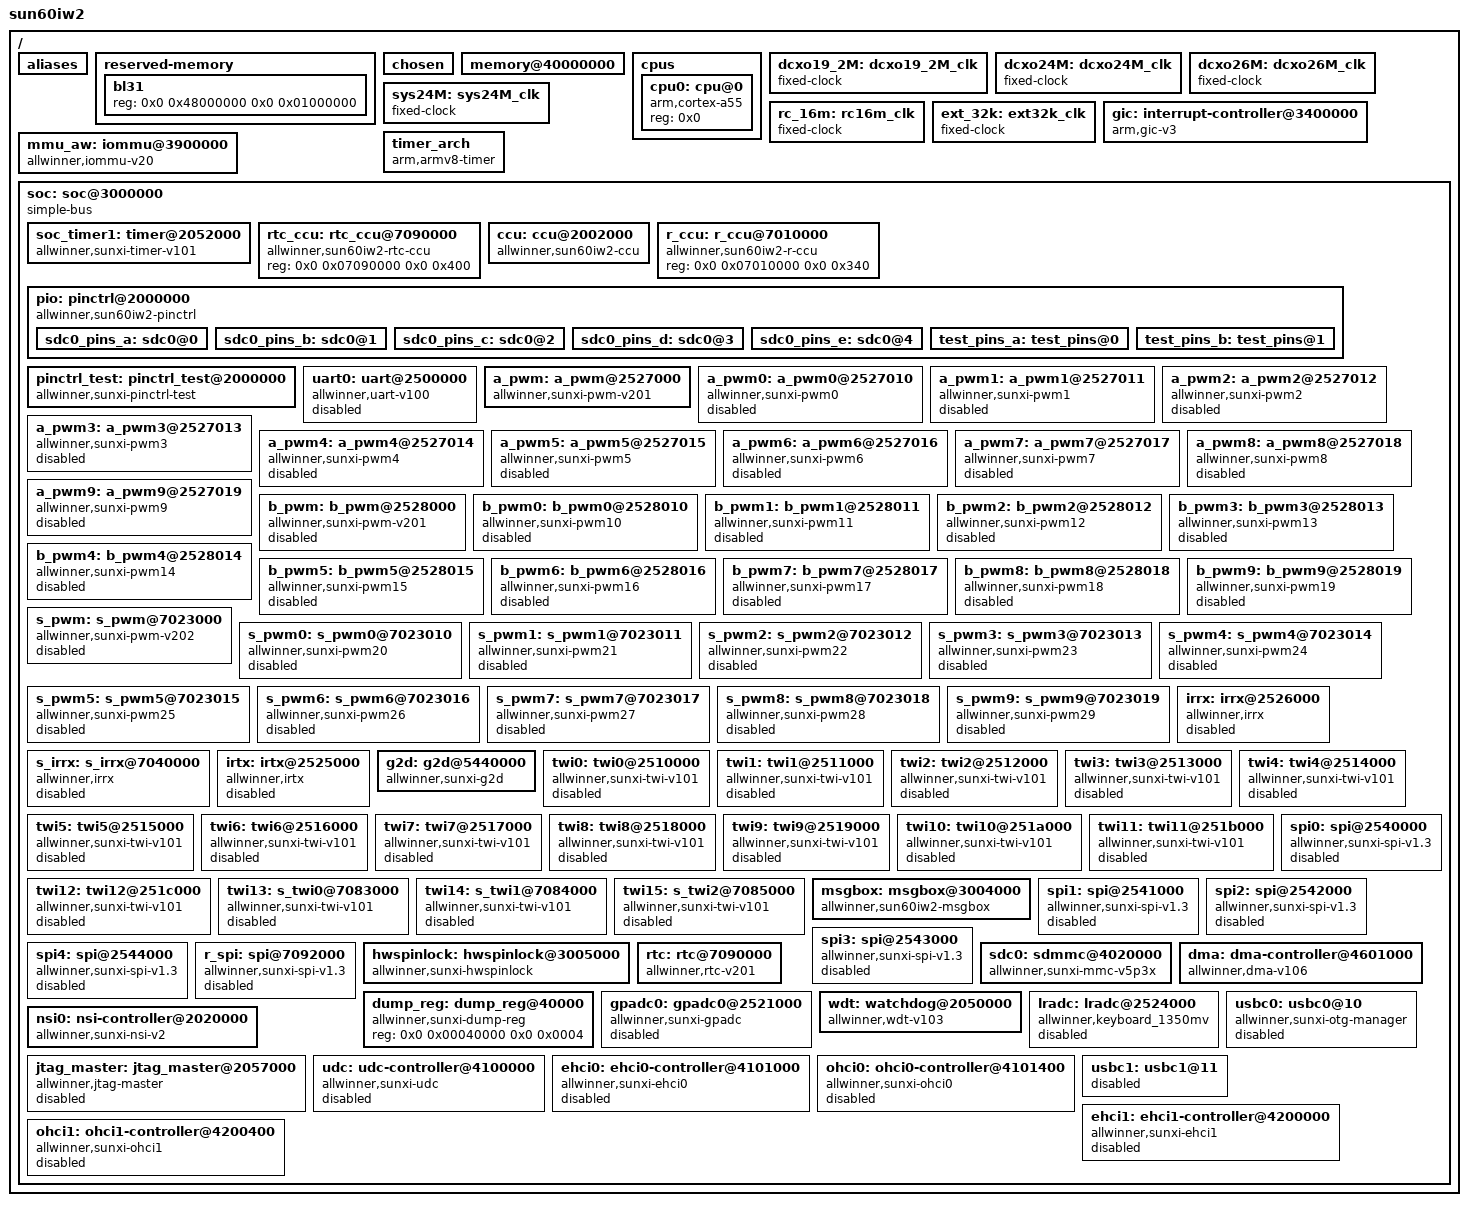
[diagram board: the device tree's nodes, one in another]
// SPDX-License-Identifier: (GPL-2.0+ or MIT)
#include <dt-bindings/clock/sun60iw2-ccu.h>
#include <dt-bindings/clock/sun60iw2-rtc.h>
#include <dt-bindings/clock/sun60iw2-r-ccu.h>
#include <dt-bindings/gpio/gpio.h>
#include <dt-bindings/gpio/sun4i-gpio.h>
#include <dt-bindings/interrupt-controller/arm-gic.h>
#include <dt-bindings/reset/sun60iw2-ccu.h>
#include <dt-bindings/reset/sun60iw2-r-ccu.h>
#include <dt-bindings/power/a523-power.h>
#include <dt-bindings/phy/phy.h>
#include <dt-bindings/thermal/thermal.h>
#include <dt-bindings/spi/sunxi-spi.h>

/ {
	model = "sun60iw2";
	interrupt-parent = <&gic>;
	#address-cells = <2>;
	#size-cells = <2>;

	aliases {
		serial0 = &uart0;
		ir0 = &irrx;
		ir1 = &s_irrx;
		ir2 = &irtx;
		twi0 = &twi0;
		twi1 = &twi1;
		twi2 = &twi2;
		twi3 = &twi3;
		twi4 = &twi4;
		twi5 = &twi5;
		twi6 = &twi6;
		twi7 = &twi7;
		twi8 = &twi8;
		twi9 = &twi9;
		twi10 = &twi10;
		twi11 = &twi11;
		twi12 = &twi12;
		twi13 = &twi13;
		twi14 = &twi14;
		twi15 = &twi15;
		spi0 = &spi0;
		spi1 = &spi1;
		spi2 = &spi2;
		spi3 = &spi3;
		spi4 = &spi4;
		spi5 = &r_spi;
	};

	reserved-memory {
		#address-cells = <2>;
		#size-cells = <2>;
		ranges;

		bl31 {
			reg = <0x0 0x48000000 0x0 0x01000000>;
		};
	};

	chosen {
		bootargs = "earlyprintk=sunxi-uart,0x2500000 loglevel=8 initcall_debug=0 console=ttyS0 init=/init";
		linux,initrd-start = <0x0 0x0>;
		linux,initrd-end = <0x0 0x0>;
	};

	/* avoid panic when memory-node err(from uboot) */
	memory@40000000 {
		device_type = "memory";
		reg = <0x00000000 0x40000000 0x00000000 0x20000000>;
	};

	cpus {
		#address-cells = <1>;
		#size-cells = <0>;

		cpu0: cpu@0 {
			device_type = "cpu";
			compatible = "arm,cortex-a55";
			reg = <0x0>;
		};
	};

	dcxo19_2M: dcxo19_2M_clk {
		#clock-cells = <0>;
		compatible = "fixed-clock";
		clock-frequency = <19200000>;
		clock-output-names = "dcxo19_2M";
	};

	dcxo24M: dcxo24M_clk {
		#clock-cells = <0>;
		compatible = "fixed-clock";
		clock-frequency = <24000000>;
		clock-output-names = "dcxo24M";
	};

	dcxo26M: dcxo26M_clk {
		#clock-cells = <0>;
		compatible = "fixed-clock";
		clock-frequency = <26000000>;
		clock-output-names = "dcxo26M";
	};

	sys24M: sys24M_clk {
		#clock-cells = <0>;
		compatible = "fixed-clock";
		clock-frequency = <24000000>;
		clock-output-names = "sys24M";
	};

	rc_16m: rc16m_clk {
		#clock-cells = <0>;
		compatible = "fixed-clock";
		clock-frequency = <16000000>;
		clock-accuracy = <300000000>;
		clock-output-names = "rc-16m";
	};

	ext_32k: ext32k_clk {
		#clock-cells = <0>;
		compatible = "fixed-clock";
		clock-frequency = <32768>;
		clock-output-names = "ext-32k";
	};

	gic: interrupt-controller@3400000 {
		compatible = "arm,gic-v3";
		#interrupt-cells = <3>;
		#address-cells = <0>;
		interrupt-controller;
		reg = <0x0 0x03400000 0 0x10000>, /* GIC Dist */
		      <0x0 0x03460000 0 0xFF004>; /* GIC Re */
		interrupt-parent = <&gic>;
	};

	timer_arch {
		compatible = "arm,armv8-timer";
		interrupts = <GIC_PPI 13 (GIC_CPU_MASK_SIMPLE(4) | IRQ_TYPE_LEVEL_LOW)>,
			   <GIC_PPI 14 (GIC_CPU_MASK_SIMPLE(4) | IRQ_TYPE_LEVEL_LOW)>,
			   <GIC_PPI 11 (GIC_CPU_MASK_SIMPLE(4) | IRQ_TYPE_LEVEL_LOW)>,
			   <GIC_PPI 10 (GIC_CPU_MASK_SIMPLE(4) | IRQ_TYPE_LEVEL_LOW)>;
		clock-frequency = <24000000>;
		interrupt-parent = <&gic>;
		arm,no-tick-in-suspend;
	};

	mmu_aw: iommu@3900000 {
		compatible = "allwinner,iommu-v20";
		reg = <0x0 0x03900000 0x0 0x20000>;
		interrupts = <GIC_SPI 170 IRQ_TYPE_LEVEL_HIGH>,
		      <GIC_SPI 171 IRQ_TYPE_LEVEL_HIGH>;
		interrupt-names = "iommu-irq1","iommu-irq2";
		clocks = <&ccu CLK_IOMMU0_SYS_HCLK>,
		      <&ccu CLK_IOMMU0_SYS_PCLK>,
		      <&ccu CLK_IOMMU0_SYS_MCLK>,
		      <&ccu CLK_IOMMU1_SYS_HCLK>,
		      <&ccu CLK_IOMMU1_SYS_PCLK>,
		      <&ccu CLK_IOMMU1_SYS_MCLK>
		;
		clock-names = "iommu0-sys-hclk",
		      "iommu0-sys-pclk",
		      "iommu0-sys-mclk",
		      "iommu1-sys-hclk",
		      "iommu1-sys-pclk",
		      "iommu1-sys-mclk"
		;
		/* clock-frequency = <24000000>; */
		#iommu-cells = <2>;
		version=<0x16>;
	tlb_prefetch = <0x3007f>;
	tlb_invalid_mode = <0x1>;
	ptw_invalid_mode = <0x1>;
	masters = "USB", "CSI", "ISP", "VE_ENC", "VE_DEC0",
			"VE_DEC1", "DE0","DI","G2D","EINK", "DEBUG_MODE";
			valid_masters=<10>;
	};

	soc: soc@3000000 {
		compatible = "simple-bus";
		#address-cells = <2>;
		#size-cells = <2>;
		ranges;

		soc_timer1: timer@2052000 {
			compatible = "allwinner,sunxi-timer-v101";
			device_type = "soc_timer";
			reg = <0x0 0x02052000 0x0 0x400>;
			interrupt-parent = <&gic>;
			interrupts = <GIC_SPI 99 IRQ_TYPE_LEVEL_HIGH>;
			clocks = <&rtc_ccu CLK_OSC32K>;
		};

		rtc_ccu: rtc_ccu@7090000 {
			compatible = "allwinner,sun60iw2-rtc-ccu";
			reg = <0x0 0x07090000 0x0 0x400>;
			#clock-cells = <1>;
			#reset-cells = <1>;
		};

		ccu: ccu@2002000 {
			compatible = "allwinner,sun60iw2-ccu";
			reg = <0x0 0x02002000 0x0 0x2000>;
			clocks = <&dcxo24M>, <&rtc_ccu CLK_OSC32K>, <&rc_16m>;
			clock-names = "hosc", "losc", "iosc";
			#clock-cells = <1>;
			#reset-cells = <1>;
		};

		r_ccu: r_ccu@7010000 {
			compatible = "allwinner,sun60iw2-r-ccu";
			reg = <0x0 0x07010000 0x0 0x340>;
			#clock-cells = <1>;
			#reset-cells = <1>;
		};

		pio: pinctrl@2000000 {
			//#address-cells = <1>;
			//#size-cells = <0>;
			compatible = "allwinner,sun60iw2-pinctrl";
			reg = <0x0 0x02000000 0x0 0x800>;
			interrupts = <GIC_SPI 69 IRQ_TYPE_LEVEL_HIGH>,
				     <GIC_SPI 71 IRQ_TYPE_LEVEL_HIGH>,
				     <GIC_SPI 73 IRQ_TYPE_LEVEL_HIGH>,
				     <GIC_SPI 75 IRQ_TYPE_LEVEL_HIGH>,
				     <GIC_SPI 77 IRQ_TYPE_LEVEL_HIGH>,
				     <GIC_SPI 79 IRQ_TYPE_LEVEL_HIGH>,
				     <GIC_SPI 81 IRQ_TYPE_LEVEL_HIGH>;
			clocks = <&ccu CLK_APB1>, <&dcxo24M>, <&rtc_ccu CLK_OSC32K>;
			clock-names = "apb", "hosc", "losc";
			gpio-controller;
			#gpio-cells = <3>;
			interrupt-controller;
			#interrupt-cells = <3>;

			sdc0_pins_a: sdc0@0 {
				pins = "PF0", "PF1", "PF2",
						"PF3", "PF4", "PF5";
				function = "sd0";
				drive-strength = <40>;
				bias-pull-up;
				power-source = <3300>;
			};

			sdc0_pins_b: sdc0@1 {
				pins = "PF0", "PF1", "PF2",
						"PF3", "PF4", "PF5";
				function = "sd0";
				drive-strength = <40>;
				bias-pull-up;
				power-source = <1800>;
			};

			sdc0_pins_c: sdc0@2 {
				pins = "PF0", "PF1", "PF2",
						"PF3", "PF4", "PF5";
				function = "gpio_in";
			};

			/* TODO: add jtag pin */
			sdc0_pins_d: sdc0@3 {
				pins = "PF2", "PF4";
				function = "uart0";
				drive-strength = <10>;
				bias-pull-up;
			};

			sdc0_pins_e: sdc0@4 {
				pins = "PF0", "PF1", "PF3",
						"PF5";
				function = "jtag";
				drive-strength = <10>;
				bias-pull-up;
			};
			test_pins_a: test_pins@0 {
				pins = "PB0", "PB1";
				function = "test";
				drive-strength = <10>;
				bias-pull-up;
			};

			test_pins_b: test_pins@1 {
				pins = "PB0", "PB1";
				function = "gpio_in";
			};
		};

		pinctrl_test: pinctrl_test@2000000 {
		      reg = <0x0 0x0 0x0 0x0>;
		      compatible = "allwinner,sunxi-pinctrl-test";
		      device_type = "pinctrl-test";
		      pinctrl-0 = <&test_pins_a>;
		      pinctrl-1 = <&test_pins_b>;
		      pinctrl-names = "default", "sleep";
		      test-gpios = <&pio PB 4 GPIO_ACTIVE_LOW>;
		      suspend-gpios = <&pio PC 5 GPIO_ACTIVE_LOW>;
		      wakeup-source;
		      interrupt-parent = <&pio>;
		      interrupts = <PB 6 IRQ_TYPE_LEVEL_HIGH>;
		};
		uart0: uart@2500000 {
			compatible = "allwinner,uart-v100";
			reg = <0x0 0x02500000 0x0 0x400>;
			interrupts = <GIC_SPI 2 IRQ_TYPE_LEVEL_HIGH>;
			clocks = <&ccu CLK_UART0>;
			resets = <&ccu RST_BUS_UART0>;
			uart0_port = <0>;
			uart0_type = <2>;
			status = "disabled";
		};

		a_pwm: a_pwm@2527000 {
			#pwm-cells = <0x3>;
			compatible = "allwinner,sunxi-pwm-v201";
			reg = <0x0 0x02527000 0x0 0x400>;
			clocks = <&ccu CLK_PWM0>;
			interrupts = <GIC_SPI 35 IRQ_TYPE_LEVEL_HIGH>;
			resets = <&ccu RST_BUS_PWM0>;
			pwm-number = <10>;
			pwm-base = <0x0>;
			sunxi-pwms = <&a_pwm0>, <&a_pwm1>, <&a_pwm2>, <&a_pwm3>, <&a_pwm4>,
			<&a_pwm5>, <&a_pwm6>, <&a_pwm7>, <&a_pwm8>, <&a_pwm9>;
			status = "okay";
		};

		a_pwm0: a_pwm0@2527010 {
			compatible = "allwinner,sunxi-pwm0";
			pinctrl-names = "active", "sleep";
			reg = <0x0 0x02527010 0x0 0x4>;
			reg_base = <0x02527000>;
			status = "disabled";
		};

		a_pwm1: a_pwm1@2527011 {
			compatible = "allwinner,sunxi-pwm1";
			pinctrl-names = "active", "sleep";
			reg = <0x0 0x02527011 0x0 0x4>;
			reg_base = <0x02527000>;
			status = "disabled";
		};

		a_pwm2: a_pwm2@2527012 {
			compatible = "allwinner,sunxi-pwm2";
			pinctrl-names = "active", "sleep";
			reg = <0x0 0x02527012 0x0 0x4>;
			reg_base = <0x02527000>;
			status = "disabled";
		};

		a_pwm3: a_pwm3@2527013 {
			compatible = "allwinner,sunxi-pwm3";
			pinctrl-names = "active", "sleep";
			reg = <0x0 0x02527013 0x0 0x4>;
			reg_base = <0x02527000>;
			status = "disabled";
		};

		a_pwm4: a_pwm4@2527014 {
			compatible = "allwinner,sunxi-pwm4";
			pinctrl-names = "active", "sleep";
			reg = <0x0 0x02527014 0x0 0x4>;
			reg_base = <0x02527000>;
			status = "disabled";
		};

		a_pwm5: a_pwm5@2527015 {
			compatible = "allwinner,sunxi-pwm5";
			pinctrl-names = "active", "sleep";
			reg = <0x0 0x02527015 0x0 0x4>;
			reg_base = <0x02527000>;
			status = "disabled";
		};

		a_pwm6: a_pwm6@2527016 {
			compatible = "allwinner,sunxi-pwm6";
			pinctrl-names = "active", "sleep";
			reg = <0x0 0x02527016 0x0 0x4>;
			reg_base = <0x02527000>;
			status = "disabled";
		};

		a_pwm7: a_pwm7@2527017 {
			compatible = "allwinner,sunxi-pwm7";
			pinctrl-names = "active", "sleep";
			reg = <0x0 0x02527017 0x0 0x4>;
			reg_base = <0x02527000>;
			status = "disabled";
		};

		a_pwm8: a_pwm8@2527018 {
			compatible = "allwinner,sunxi-pwm8";
			pinctrl-names = "active", "sleep";
			reg = <0x0 0x02527018 0x0 0x4>;
			reg_base = <0x02527000>;
			status = "disabled";
		};

		a_pwm9: a_pwm9@2527019 {
			compatible = "allwinner,sunxi-pwm9";
			pinctrl-names = "active", "sleep";
			reg = <0x0 0x02527019 0x0 0x4>;
			reg_base = <0x02527000>;
			status = "disabled";
		};

		b_pwm: b_pwm@2528000 {
			#pwm-cells = <0x3>;
			compatible = "allwinner,sunxi-pwm-v201";
			reg = <0x0 0x02528000 0x0 0x400>;
			clocks = <&ccu CLK_PWM1>;
			interrupts = <GIC_SPI 36 IRQ_TYPE_LEVEL_HIGH>;
			resets = <&ccu RST_BUS_PWM1>;
			pwm-number = <10>;
			pwm-base = <0xa>;
			sunxi-pwms = <&b_pwm0>, <&b_pwm1>, <&b_pwm2>, <&b_pwm3>,
			<&b_pwm4>, <&b_pwm5>, <&b_pwm6>, <&b_pwm7>, <&b_pwm8>, <&b_pwm9>;
			status = "disabled";
		};

		b_pwm0: b_pwm0@2528010 {
			compatible = "allwinner,sunxi-pwm10";
			pinctrl-names = "active", "sleep";
			reg = <0x0 0x02528010 0x0 0x4>;
			reg_base = <0x02528000>;
			status = "disabled";
		};

		b_pwm1: b_pwm1@2528011 {
			compatible = "allwinner,sunxi-pwm11";
			pinctrl-names = "active", "sleep";
			reg = <0x0 0x02528011 0x0 0x4>;
			reg_base = <0x02528000>;
			status = "disabled";
		};

		b_pwm2: b_pwm2@2528012 {
			compatible = "allwinner,sunxi-pwm12";
			pinctrl-names = "active", "sleep";
			reg = <0x0 0x02528012 0x0 0x4>;
			reg_base = <0x02528000>;
			status = "disabled";
		};

		b_pwm3: b_pwm3@2528013 {
			compatible = "allwinner,sunxi-pwm13";
			pinctrl-names = "active", "sleep";
			reg = <0x0 0x02528013 0x0 0x4>;
			reg_base = <0x02528000>;
			status = "disabled";
		};

		b_pwm4: b_pwm4@2528014 {
			compatible = "allwinner,sunxi-pwm14";
			pinctrl-names = "active", "sleep";
			reg = <0x0 0x02528014 0x0 0x4>;
			reg_base = <0x02528000>;
			status = "disabled";
		};

		b_pwm5: b_pwm5@2528015 {
			compatible = "allwinner,sunxi-pwm15";
			pinctrl-names = "active", "sleep";
			reg = <0x0 0x02528015 0x0 0x4>;
			reg_base = <0x02528000>;
			status = "disabled";
		};

		b_pwm6: b_pwm6@2528016 {
			compatible = "allwinner,sunxi-pwm16";
			pinctrl-names = "active", "sleep";
			reg = <0x0 0x02528016 0x0 0x4>;
			reg_base = <0x02528000>;
			status = "disabled";
		};

		b_pwm7: b_pwm7@2528017 {
			compatible = "allwinner,sunxi-pwm17";
			pinctrl-names = "active", "sleep";
			reg = <0x0 0x02528017 0x0 0x4>;
			reg_base = <0x02528000>;
			status = "disabled";
		};

		b_pwm8: b_pwm8@2528018 {
			compatible = "allwinner,sunxi-pwm18";
			pinctrl-names = "active", "sleep";
			reg = <0x0 0x02528018 0x0 0x4>;
			reg_base = <0x02528000>;
			status = "disabled";
		};

		b_pwm9: b_pwm9@2528019 {
			compatible = "allwinner,sunxi-pwm19";
			pinctrl-names = "active", "sleep";
			reg = <0x0 0x02528019 0x0 0x4>;
			reg_base = <0x02528000>;
			status = "disabled";
		};

		s_pwm: s_pwm@7023000 {
			#pwm-cells = <0x3>;
			compatible = "allwinner,sunxi-pwm-v202";
			reg = <0x0 0x07023000 0x0 0x400>;
			clocks = <&r_ccu CLK_R_PWM>,<&r_ccu CLK_R_BUS_PWM>;
			interrupts = <GIC_SPI 207 IRQ_TYPE_LEVEL_HIGH>;
			clock-names = "clk_pwm","clk_bus_pwm";
			resets = <&r_ccu RST_BUS_R_PWM>;
			pwm-number = <10>;
			pwm-base = <0x14>;
			sunxi-pwms = <&s_pwm0>, <&s_pwm1>, <&s_pwm2>, <&s_pwm3>,
			<&s_pwm4>, <&s_pwm5>, <&s_pwm6>, <&s_pwm7>, <&s_pwm8>, <&s_pwm9>;
			status = "disabled";
		};

		s_pwm0: s_pwm0@7023010 {
			compatible = "allwinner,sunxi-pwm20";
			pinctrl-names = "active", "sleep";
			reg = <0x0 0x07023010 0x0 0x4>;
			reg_base = <0x07023000>;
			status = "disabled";
		};

		s_pwm1: s_pwm1@7023011 {
			compatible = "allwinner,sunxi-pwm21";
			pinctrl-names = "active", "sleep";
			reg = <0x0 0x07023011 0x0 0x4>;
			reg_base = <0x07023000>;
			status = "disabled";
		};

		s_pwm2: s_pwm2@7023012 {
			compatible = "allwinner,sunxi-pwm22";
			pinctrl-names = "active", "sleep";
			reg = <0x0 0x07023012 0x0 0x4>;
			reg_base = <0x07023000>;
			status = "disabled";
		};

		s_pwm3: s_pwm3@7023013 {
			compatible = "allwinner,sunxi-pwm23";
			pinctrl-names = "active", "sleep";
			reg = <0x0 0x07023013 0x0 0x4>;
			reg_base = <0x07023000>;
			status = "disabled";
		};

		s_pwm4: s_pwm4@7023014 {
			compatible = "allwinner,sunxi-pwm24";
			pinctrl-names = "active", "sleep";
			reg = <0x0 0x07023014 0x0 0x4>;
			reg_base = <0x07023000>;
			status = "disabled";
		};

		s_pwm5: s_pwm5@7023015 {
			compatible = "allwinner,sunxi-pwm25";
			pinctrl-names = "active", "sleep";
			reg = <0x0 0x07023015 0x0 0x4>;
			reg_base = <0x07023000>;
			status = "disabled";
		};

		s_pwm6: s_pwm6@7023016 {
			compatible = "allwinner,sunxi-pwm26";
			pinctrl-names = "active", "sleep";
			reg = <0x0 0x07023016 0x0 0x4>;
			reg_base = <0x07023000>;
			status = "disabled";
		};

		s_pwm7: s_pwm7@7023017 {
			compatible = "allwinner,sunxi-pwm27";
			pinctrl-names = "active", "sleep";
			reg = <0x0 0x07023017 0x0 0x4>;
			reg_base = <0x07023000>;
			status = "disabled";
		};

		s_pwm8: s_pwm8@7023018 {
			compatible = "allwinner,sunxi-pwm28";
			pinctrl-names = "active", "sleep";
			reg = <0x0 0x07023018 0x0 0x4>;
			reg_base = <0x07023000>;
			status = "disabled";
		};

		s_pwm9: s_pwm9@7023019 {
			compatible = "allwinner,sunxi-pwm29";
			pinctrl-names = "active", "sleep";
			reg = <0x0 0x07023019 0x0 0x4>;
			reg_base = <0x07023000>;
			status = "disabled";
		};

		irrx: irrx@2526000 {
			compatible = "allwinner,irrx";
			reg = <0x0 0x02526000 0x0 0x400>;
			interrupts = <GIC_SPI 32 IRQ_TYPE_LEVEL_HIGH>;
			clocks = <&ccu CLK_BUS_IRRX>, <&dcxo24M>, <&ccu CLK_IRRX>;
			clock-names = "bus", "pclk", "mclk";
			resets = <&ccu RST_BUS_IRRX>;
			status = "disabled";
		};

		s_irrx: s_irrx@7040000 {
			compatible = "allwinner,irrx";
			reg = <0x0 0x07040000 0x0 0x400>;
			interrupts = <GIC_SPI 206 IRQ_TYPE_LEVEL_HIGH>;
			clocks = <&r_ccu CLK_R_BUS_IRRX>, <&dcxo24M>, <&r_ccu CLK_R_IRRX>;
			clock-names = "bus", "pclk", "mclk";
			resets = <&r_ccu RST_BUS_R_IRRX>;
			status = "disabled";
		};

		irtx: irtx@2525000 {
			compatible = "allwinner,irtx";
			reg = <0x0 0x02525000 0x0 0x400>;
			interrupts = <GIC_SPI 31 IRQ_TYPE_LEVEL_HIGH>;
			clocks = <&ccu CLK_BUS_IRTX>, <&dcxo24M>, <&ccu CLK_IRTX>;
			clock-names = "bus", "pclk", "mclk";
			resets = <&ccu RST_BUS_IRTX>;
			status = "disabled";
		};

		g2d: g2d@5440000 {
			compatible = "allwinner,sunxi-g2d";
			reg = <0x0 0x05440000 0x0 0x30000>;
			interrupts = <GIC_SPI 51 IRQ_TYPE_LEVEL_HIGH>;
			clocks = <&ccu CLK_BUS_G2D>, <&ccu CLK_G2D>;
			clock-names = "bus", "g2d";
			resets = <&ccu RST_BUS_G2D>;
			iommus = <&mmu_aw 10 1>;
			assigned-clocks = <&ccu CLK_G2D>;
			assigned-clock-rates = <300000000>;
		};

		twi0: twi0@2510000 {
			#address-cells = <1>;
			#size-cells = <0>;
			compatible = "allwinner,sunxi-twi-v101";
			device_type = "twi0";
			reg = <0x0 0x02510000 0x0 0x400>;
			interrupts = <GIC_SPI 11 IRQ_TYPE_LEVEL_HIGH>;
			clocks = <&ccu CLK_TWI0>;
			clock-names = "bus";
			resets = <&ccu RST_BUS_TWI0>;
			dmas = <&dma 37>, <&dma 37>;
			dma-names = "tx", "rx";
			status = "disabled";
		};

		twi1: twi1@2511000 {
			#address-cells = <1>;
			#size-cells = <0>;
			compatible = "allwinner,sunxi-twi-v101";
			device_type = "twi1";
			reg = <0x0 0x02511000 0x0 0x400>;
			interrupts = <GIC_SPI 12 IRQ_TYPE_LEVEL_HIGH>;
			clocks = <&ccu CLK_TWI1>;
			clock-names = "bus";
			resets = <&ccu RST_BUS_TWI1>;
			dmas = <&dma 38>, <&dma 38>;
			dma-names = "tx", "rx";
			status = "disabled";
		};

		twi2: twi2@2512000 {
			#address-cells = <1>;
			#size-cells = <0>;
			compatible = "allwinner,sunxi-twi-v101";
			device_type = "twi2";
			reg = <0x0 0x02512000 0x0 0x400>;
			interrupts = <GIC_SPI 13 IRQ_TYPE_LEVEL_HIGH>;
			clocks = <&ccu CLK_TWI2>;
			clock-names = "bus";
			resets = <&ccu RST_BUS_TWI2>;
			dmas = <&dma 39>, <&dma 39>;
			dma-names = "tx", "rx";
			status = "disabled";
		};

		twi3: twi3@2513000 {
			#address-cells = <1>;
			#size-cells = <0>;
			compatible = "allwinner,sunxi-twi-v101";
			device_type = "twi3";
			reg = <0x0 0x02513000 0x0 0x400>;
			interrupts = <GIC_SPI 14 IRQ_TYPE_LEVEL_HIGH>;
			clocks = <&ccu CLK_TWI3>;
			clock-names = "bus";
			resets = <&ccu RST_BUS_TWI3>;
			dmas = <&dma 40>, <&dma 40>;
			dma-names = "tx", "rx";
			status = "disabled";
		};

		twi4: twi4@2514000 {
			#address-cells = <1>;
			#size-cells = <0>;
			compatible = "allwinner,sunxi-twi-v101";
			device_type = "twi4";
			reg = <0x0 0x02514000 0x0 0x400>;
			interrupts = <GIC_SPI 15 IRQ_TYPE_LEVEL_HIGH>;
			clocks = <&ccu CLK_TWI4>;
			clock-names = "bus";
			resets = <&ccu RST_BUS_TWI4>;
			dmas = <&dma 41>, <&dma 41>;
			dma-names = "tx", "rx";
			status = "disabled";
		};

		twi5: twi5@2515000 {
			#address-cells = <1>;
			#size-cells = <0>;
			compatible = "allwinner,sunxi-twi-v101";
			device_type = "twi5";
			reg = <0x0 0x02515000 0x0 0x400>;
			interrupts = <GIC_SPI 16 IRQ_TYPE_LEVEL_HIGH>;
			clocks = <&ccu CLK_TWI5>;
			clock-names = "bus";
			resets = <&ccu RST_BUS_TWI5>;
			dmas = <&dma 42>, <&dma 42>;
			dma-names = "tx", "rx";
			status = "disabled";
		};

		twi6: twi6@2516000 {
			#address-cells = <1>;
			#size-cells = <0>;
			compatible = "allwinner,sunxi-twi-v101";
			device_type = "twi6";
			reg = <0x0 0x02516000 0x0 0x400>;
			interrupts = <GIC_SPI 17 IRQ_TYPE_LEVEL_HIGH>;
			clocks = <&ccu CLK_TWI6>;
			clock-names = "bus";
			resets = <&ccu RST_BUS_TWI6>;
			dmas = <&dma 43>, <&dma 43>;
			dma-names = "tx", "rx";
			status = "disabled";
		};

		twi7: twi7@2517000 {
			#address-cells = <1>;
			#size-cells = <0>;
			compatible = "allwinner,sunxi-twi-v101";
			device_type = "twi7";
			reg = <0x0 0x02517000 0x0 0x400>;
			interrupts = <GIC_SPI 18 IRQ_TYPE_LEVEL_HIGH>;
			clocks = <&ccu CLK_TWI7>;
			clock-names = "bus";
			resets = <&ccu RST_BUS_TWI7>;
			dmas = <&dma 44>, <&dma 44>;
			dma-names = "tx", "rx";
			status = "disabled";
		};

		twi8: twi8@2518000 {
			#address-cells = <1>;
			#size-cells = <0>;
			compatible = "allwinner,sunxi-twi-v101";
			device_type = "twi8";
			reg = <0x0 0x02518000 0x0 0x400>;
			interrupts = <GIC_SPI 19 IRQ_TYPE_LEVEL_HIGH>;
			clocks = <&ccu CLK_TWI8>;
			clock-names = "bus";
			resets = <&ccu RST_BUS_TWI8>;
			dmas = <&dma 45>, <&dma 45>;
			dma-names = "tx", "rx";
			status = "disabled";
		};

		twi9: twi9@2519000 {
			#address-cells = <1>;
			#size-cells = <0>;
			compatible = "allwinner,sunxi-twi-v101";
			device_type = "twi9";
			reg = <0x0 0x02519000 0x0 0x400>;
			interrupts = <GIC_SPI 20 IRQ_TYPE_LEVEL_HIGH>;
			clocks = <&ccu CLK_TWI9>;
			clock-names = "bus";
			resets = <&ccu RST_BUS_TWI9>;
			dmas = <&dma 58>, <&dma 58>;
			dma-names = "tx", "rx";
			status = "disabled";
		};

		twi10: twi10@251a000 {
			#address-cells = <1>;
			#size-cells = <0>;
			compatible = "allwinner,sunxi-twi-v101";
			device_type = "twi10";
			reg = <0x0 0x0251a000 0x0 0x400>;
			interrupts = <GIC_SPI 21 IRQ_TYPE_LEVEL_HIGH>;
			clocks = <&ccu CLK_TWI10>;
			clock-names = "bus";
			resets = <&ccu RST_BUS_TWI10>;
			dmas = <&dma 59>, <&dma 59>;
			dma-names = "tx", "rx";
			status = "disabled";
		};

		twi11: twi11@251b000 {
			#address-cells = <1>;
			#size-cells = <0>;
			compatible = "allwinner,sunxi-twi-v101";
			device_type = "twi11";
			reg = <0x0 0x0251b000 0x0 0x400>;
			interrupts = <GIC_SPI 22 IRQ_TYPE_LEVEL_HIGH>;
			clocks = <&ccu CLK_TWI11>;
			clock-names = "bus";
			resets = <&ccu RST_BUS_TWI11>;
			dmas = <&dma 60>, <&dma 60>;
			dma-names = "tx", "rx";
			status = "disabled";
		};

		twi12: twi12@251c000 {
			#address-cells = <1>;
			#size-cells = <0>;
			compatible = "allwinner,sunxi-twi-v101";
			device_type = "twi12";
			reg = <0x0 0x0251c000 0x0 0x400>;
			interrupts = <GIC_SPI 23 IRQ_TYPE_LEVEL_HIGH>;
			clocks = <&ccu CLK_TWI12>;
			clock-names = "bus";
			resets = <&ccu RST_BUS_TWI12>;
			dmas = <&dma 61>, <&dma 61>;
			dma-names = "tx", "rx";
			status = "disabled";
		};

		twi13: s_twi0@7083000 {
			#address-cells = <1>;
			#size-cells = <0>;
			compatible = "allwinner,sunxi-twi-v101";
			device_type = "twi13";
			reg = <0x0 0x07083000 0x0 0x400>;
			interrupts = <GIC_SPI 203 IRQ_TYPE_LEVEL_HIGH>;
			clocks = <&r_ccu CLK_R_TWI0>;
			clock-names = "bus";
			resets = <&r_ccu RST_BUS_R_TWI0>;
			dmas = <&dma 47>, <&dma 47>;
			dma-names = "tx", "rx";
			status = "disabled";
		};

		twi14: s_twi1@7084000 {
			#address-cells = <1>;
			#size-cells = <0>;
			compatible = "allwinner,sunxi-twi-v101";
			device_type = "twi14";
			reg = <0x0 0x07084000 0x0 0x400>;
			interrupts = <GIC_SPI 204 IRQ_TYPE_LEVEL_HIGH>;
			clocks = <&r_ccu CLK_R_TWI1>;
			clock-names = "bus";
			resets = <&r_ccu RST_BUS_R_TWI1>;
			dmas = <&dma 48>, <&dma 48>;
			dma-names = "tx", "rx";
			status = "disabled";
		};

		twi15: s_twi2@7085000 {
			#address-cells = <1>;
			#size-cells = <0>;
			compatible = "allwinner,sunxi-twi-v101";
			device_type = "twi15";
			reg = <0x0 0x07085000 0x0 0x400>;
			interrupts = <GIC_SPI 205 IRQ_TYPE_LEVEL_HIGH>;
			clocks = <&r_ccu CLK_R_TWI>;
			clock-names = "bus";
			resets = <&r_ccu RST_BUS_R_TWI>;
			dmas = <&dma 49>, <&dma 49>;
			dma-names = "tx", "rx";
			status = "disabled";
		};

		/*
		 * channel0~3  : arm -> cpus
		 */
		msgbox: msgbox@3004000 {
			compatible = "allwinner,sun60iw2-msgbox";
			#mbox-cells = <1>;
			reg = <0x0 0x03004000 0x0 0x1000>,
			      <0x0 0x07094000 0x0 0x1000>;
			interrupts = <GIC_SPI 0 IRQ_TYPE_LEVEL_HIGH>,
					<GIC_SPI 211 IRQ_TYPE_LEVEL_HIGH>;
			clocks = <&ccu CLK_MSGBOX0>;
			clock-names = "msgbox";
			resets = <&ccu RST_BUS_MSGBOX0>;
			reset-names = "rst";
			local_id = <0>;
			status = "okay";
		};

		spi0: spi@2540000 {
			#address-cells = <1>;
			#size-cells = <0>;
			compatible = "allwinner,sunxi-spi-v1.3";
			device_type = "spi0";
			reg = <0x0 0x02540000 0x0 0x1000>;
			interrupts = <GIC_SPI 24 IRQ_TYPE_LEVEL_HIGH>;
			clocks = <&ccu CLK_PLL_PERI0_300M>, <&ccu CLK_SPI0>, <&ccu CLK_BUS_SPI0>;
			clock-names = "pll", "mod", "bus";
			clock-frequency = <100000000>;
			resets = <&ccu RST_BUS_SPI0>;
			dmas = <&dma 23>, <&dma 23>;
			dma-names = "tx", "rx";
			status = "disabled";
		};

		spi1: spi@2541000 {
			#address-cells = <1>;
			#size-cells = <0>;
			compatible = "allwinner,sunxi-spi-v1.3";
			device_type = "spi1";
			reg = <0x0 0x02541000 0x0 0x1000>;
			interrupts = <GIC_SPI 25 IRQ_TYPE_LEVEL_HIGH>;
			clocks = <&ccu CLK_PLL_PERI0_300M>, <&ccu CLK_SPI1>, <&ccu CLK_BUS_SPI1>;
			clock-names = "pll", "mod", "bus";
			clock-frequency = <100000000>;
			resets = <&ccu RST_BUS_SPI1>;
			dmas = <&dma 24>, <&dma 24>;
			dma-names = "tx", "rx";
			status = "disabled";
		};

		spi2: spi@2542000 {
			#address-cells = <1>;
			#size-cells = <0>;
			compatible = "allwinner,sunxi-spi-v1.3";
			device_type = "spi2";
			reg = <0x0 0x02542000 0x0 0x1000>;
			interrupts = <GIC_SPI 26 IRQ_TYPE_LEVEL_HIGH>;
			clocks = <&ccu CLK_PLL_PERI0_300M>, <&ccu CLK_SPI2>, <&ccu CLK_BUS_SPI2>;
			clock-names = "pll", "mod", "bus";
			clock-frequency = <100000000>;
			resets = <&ccu RST_BUS_SPI2>;
			dmas = <&dma 25>, <&dma 25>;
			dma-names = "tx", "rx";
			status = "disabled";
		};

		spi3: spi@2543000 {
			#address-cells = <1>;
			#size-cells = <0>;
			compatible = "allwinner,sunxi-spi-v1.3";
			device_type = "spi3";
			reg = <0x0 0x02543000 0x0 0x1000>;
			interrupts = <GIC_SPI 27 IRQ_TYPE_LEVEL_HIGH>;
			clocks = <&ccu CLK_PLL_PERI0_300M>, <&ccu CLK_SPI3>, <&ccu CLK_BUS_SPI3>;
			clock-names = "pll", "mod", "bus";
			clock-frequency = <100000000>;
			resets = <&ccu RST_BUS_SPI3>;
			dmas = <&dma 26>, <&dma 26>;
			dma-names = "tx", "rx";
			status = "disabled";
		};

		spi4: spi@2544000 {
			#address-cells = <1>;
			#size-cells = <0>;
			compatible = "allwinner,sunxi-spi-v1.3";
			device_type = "spi4";
			reg = <0x0 0x02544000 0x0 0x1000>;
			interrupts = <GIC_SPI 28 IRQ_TYPE_LEVEL_HIGH>;
			clocks = <&ccu CLK_PLL_PERI0_300M>, <&ccu CLK_SPI4>, <&ccu CLK_BUS_SPI4>;
			clock-names = "pll", "mod", "bus";
			clock-frequency = <100000000>;
			resets = <&ccu RST_BUS_SPI4>;
			dmas = <&dma 54>, <&dma 54>;
			dma-names = "tx", "rx";
			status = "disabled";
		};

		r_spi: spi@7092000 {
			#address-cells = <1>;
			#size-cells = <0>;
			compatible = "allwinner,sunxi-spi-v1.3";
			device_type = "r_spi";
			reg = <0x0 0x07092000 0x0 0x1000>;
			interrupts = <GIC_SPI 210 IRQ_TYPE_LEVEL_HIGH>;
			clocks = <&ccu CLK_PLL_PERI0_300M>, <&r_ccu CLK_R_SPI>, <&r_ccu CLK_R_BUS_SPI>;
			clock-names = "pll", "mod", "bus";
			clock-frequency = <100000000>;
			resets = <&r_ccu RST_BUS_R_SPI>;
			dmas = <&dma 53>, <&dma 53>;
			dma-names = "tx", "rx";
			status = "disabled";
		};

		hwspinlock: hwspinlock@3005000 {
			compatible = "allwinner,sunxi-hwspinlock";
			reg = <0x0 0x3005000 0x0 0x1000>;
			#hwlock-cells = <1>;
			clocks = <&ccu CLK_SPINLOCK>;
			clock-names = "clk_hwspinlock_bus";
			resets = <&ccu RST_BUS_SPINLOCK>;
			reset-names = "rst";
			num-locks = <32>;
			status = "okay";
		};

		sdc0: sdmmc@4020000 {
			compatible = "allwinner,sunxi-mmc-v5p3x";
			device_type = "sdc0";
			reg = <0x0 0x04020000 0x0 0x1000>;
			interrupts = <GIC_SPI 161 IRQ_TYPE_LEVEL_HIGH>;
			clocks = <&sys24M>,
				 <&ccu CLK_SMHC0>,
				 <&ccu CLK_BUS_SMHC0>;
			clock-names = "osc24m","mmc","ahb";
			resets = <&ccu RST_BUS_SMHC0>;
			reset-names = "rst";
			pinctrl-names = "default","mmc_1v8","sleep","uart_jtag";
			pinctrl-0 = <&sdc0_pins_a>;
			pinctrl-1 = <&sdc0_pins_b>;
			pinctrl-2 = <&sdc0_pins_c>;
			pinctrl-3 = <&sdc0_pins_d &sdc0_pins_e>;
			max-frequency = <50000000>;
			bus-width = <4>;
			req-page-count = <2>;
			/*non-removable;*/
			/*broken-cd;*/
			/*cd-inverted*/
			/*cd-gpios = <&pio PF 6 GPIO_ACTIVE_LOW>;*/
			/* vmmc-supply = <&reg_3p3v>;*/
			/* vqmc-supply = <&reg_3p3v>;*/
			/* vdmc-supply = <&reg_3p3v>;*/
			/*vmmc = "vcc-card";*/
			/*vqmc = "";*/
			/*vdmc = "";*/
			cap-sd-highspeed;
			cap-wait-while-busy;
			/*sd-uhs-sdr50;*/
			/*sd-uhs-ddr50;*/
			/*cap-sdio-irq;*/
			/*keep-power-in-suspend;*/
			/*ignore-pm-notify;*/
			/*sunxi-power-save-mode;*/
			/*sunxi-dly-400k = <1 0 0 0>; */
			/*sunxi-dly-26M  = <1 0 0 0>;*/
			/*sunxi-dly-52M  = <1 0 0 0>;*/
			/*sunxi-dly-52M-ddr4  = <1 0 0 0>;*/
			/*sunxi-dly-52M-ddr8  = <1 0 0 0>;*/
			/*sunxi-dly-104M  = <1 0 0 0>;*/
			/*sunxi-dly-208M  = <1 0 0 0>;*/
			/*sunxi-dly-104M-ddr  = <1 0 0 0>;*/
			/*sunxi-dly-208M-ddr  = <1 0 0 0>;*/
			ctl-spec-caps = <0x408>;
			status = "okay";
		};

		rtc: rtc@7090000 {
			compatible = "allwinner,rtc-v201";
			device_type = "rtc";
			wakeup-source;
			reg = <0x0 0x07090000 0x0 0x320>;
			interrupts = <GIC_SPI 196 IRQ_TYPE_LEVEL_HIGH>;
			clocks = <&r_ccu CLK_RTC>, <&rtc_ccu CLK_RTC_1K>, <&rtc_ccu CLK_RTC_SPI>;
			clock-names = "r-ahb-rtc", "rtc-1k", "rtc-spi";
			resets = <&r_ccu RST_BUS_RTC>;
			gpr_cur_pos = <6>;
			gpr_bootcount_pos = <7>;
		};

		dma: dma-controller@4601000 {
			compatible = "allwinner,dma-v106";
			reg = <0x0 0x04601000 0x0 0x2000>;
			interrupts = <GIC_SPI 111 IRQ_TYPE_LEVEL_HIGH>;
			clocks = <&ccu CLK_DMA0_BUS>, <&ccu CLK_DMA0_MBUS>;
			clock-names = "bus", "mbus";
			dma-channels = <16>;
			dma-requests = <64>;
			resets = <&ccu RST_BUS_DMA0>;
			#dma-cells = <1>;
		};

		dump_reg:dump_reg@40000 {
			compatible = "allwinner,sunxi-dump-reg";
			reg = <0x0 0x00040000 0x0 0x0004>;
		};

		gpadc0: gpadc0@2521000 {
			compatible = "allwinner,sunxi-gpadc";
			reg = <0x0 0x02521000 0x0 0x400>;
			interrupts = <GIC_SPI 38 IRQ_TYPE_LEVEL_HIGH>;
			clocks = <&ccu CLK_GPADC0>;
			clock-names = "bus";
			resets = <&ccu RST_BUS_GPADC0>;
			status = "disabled";
		};

		wdt: watchdog@2050000 {
			compatible = "allwinner,wdt-v103";
			reg = <0x0 0x02050000 0x0 0x20>;
			interrupts = <GIC_SPI 106 IRQ_TYPE_LEVEL_HIGH>;
		};

		lradc: lradc@2524000 {
			compatible = "allwinner,keyboard_1350mv";
			reg = <0x0 0x02524000 0x0 0x100>;
			interrupts = <GIC_SPI 37 IRQ_TYPE_LEVEL_HIGH>;
			clocks = <&ccu CLK_LRADC>;
			resets = <&ccu RST_BUS_LRADC>;
			status = "disabled";
		};

		nsi0: nsi-controller@2020000 {
			compatible = "allwinner,sunxi-nsi-v2";
			interrupts = <GIC_SPI 43 IRQ_TYPE_LEVEL_HIGH>;
			reg = <0x0 0x02020000 0x0 0x10000>;
			clocks = <&ccu CLK_DDRPLL>, <&ccu CLK_MBUS>,<&ccu CLK_NSI>,<&ccu CLK_PLL_PERI0_800M>,<&ccu CLK_GIC>;
			clock-names = "pll", "bus", "nsi", "nsi-p","gic";
			resets = <&ccu RST_BUS_NSI>, <&ccu RST_BUS_NSI_CFG>;
			clock-frequency = <462000000>,<800000000>;
			#nsi-cells = <1>;
			clk_path_type=<1>;
			topology_type=<2>;
			master_clks = <6 2>,<10 4>,<18 2>,<19 2>,<20 2>;
		};

		jtag_master: jtag_master@2057000 {
			compatible = "allwinner,jtag-master";
			reg = <0x0 0x02057000 0x0 0x1000>;
			clocks = <&ccu CLK_APB2JTAG>;
			clock-names = "apb2jtag-clk";
			resets = <&ccu RST_BUS_APB2JTAG>;
			reset-names = "apb2jtag-rst";
			status = "disabled";
		};

		usbc0: usbc0@10 {
			device_type = "usbc0";
			compatible = "allwinner,sunxi-otg-manager";
			reg = <0x0 0x10 0x0 0x1000>;
			usb_port_type = <2>;
			usb_detect_type = <1>;
			usb_detect_mode = <0>;
			usb_id_gpio;
			usb_det_vbus_gpio;
			usb_regulator_io = "nocare";
			usb_wakeup_suspend = <0>;
			usb_luns = <3>;
			usb_serial_unique = <0>;
			usb_serial_number = "20080411";
			rndis_wceis = <1>;
			status = "disabled";
		};

		udc:udc-controller@4100000 {
			compatible = "allwinner,sunxi-udc";
			reg = <0x0 0x04100000 0x0 0x1000>, /* udc base */
			      <0x0 0x00000000 0x0 0x100>;  /* sram base */
			interrupts = <GIC_SPI 156 IRQ_TYPE_LEVEL_HIGH>;
			clocks = <&ccu CLK_USB0_DEVICE>;
			clock-names = "bus_otg";
			resets = <&ccu RST_USB_0_DEVICE>, <&ccu RST_USB_0_PHY_RSTN>;
			reset-names = "otg", "phy";
			status = "disabled";
		};

		ehci0:ehci0-controller@4101000 {
			compatible = "allwinner,sunxi-ehci0";
			reg = <0x0 0x04101000 0x0 0xFFF>,  /*hci0 base*/
			      <0x0 0x00000000 0x0 0x100>,  /*sram base*/
			      <0x0 0x04100000 0x0 0x1000>; /*otg base*/
			interrupts = <GIC_SPI 157 IRQ_TYPE_LEVEL_HIGH>;
			clocks = <&ccu CLK_USB0_EHCI>;
			clock-names = "bus_hci";
			resets = <&ccu RST_USB_0_EHCI>, <&ccu RST_USB_0_PHY_RSTN>;
			reset-names = "hci", "phy";
			hci_ctrl_no = <0>;
			status = "disabled";
		};

		ohci0:ohci0-controller@4101400 {
			compatible = "allwinner,sunxi-ohci0";
			reg = <0x0 0x04101400 0x0 0xFFF>,  /*hci0 base*/
			      <0x0 0x00000000 0x0 0x100>,  /*sram base*/
			      <0x0 0x04100000 0x0 0x1000>; /*otg base*/
			interrupts = <GIC_SPI 158 IRQ_TYPE_LEVEL_HIGH>;
			clocks = <&ccu CLK_USB0_OHCI>, <&ccu CLK_USB>;
			clock-names = "bus_hci", "ohci";
			resets = <&ccu RST_USB_0_OHCI>, <&ccu RST_USB_0_PHY_RSTN>;
			reset-names = "hci", "phy";
			hci_ctrl_no = <0>;
			status = "disabled";
		};

		usbc1: usbc1@11 {
			device_type = "usbc1";
			reg = <0x0 0x11 0x0 0x1000>;
			usb_regulator_io = "nocare";
			usb_wakeup_suspend = <0>;
			status = "disabled";
		};

		ehci1: ehci1-controller@4200000 {
			compatible = "allwinner,sunxi-ehci1";
			reg = <0x0 0x04200000 0x0 0xFFF>,  /*ehci1 base*/
			      <0x0 0x00000000 0x0 0x100>,  /*sram base*/
			      <0x0 0x04100000 0x0 0x1000>; /*otg base*/
			interrupts = <GIC_SPI 159 IRQ_TYPE_LEVEL_HIGH>;
			clocks = <&ccu CLK_USB1_EHCI>;
			clock-names = "bus_hci";
			resets = <&ccu RST_USB_1_EHCI>, <&ccu RST_USB_1_PHY_RSTN>;
			reset-names = "hci", "phy";
			hci_ctrl_no = <1>;
			status = "disabled";
		};

		ohci1: ohci1-controller@4200400 {
			compatible = "allwinner,sunxi-ohci1";
			reg = <0x0 0x04200400 0x0 0xFFF>,  /*ohci1 base*/
			      <0x0 0x00000000 0x0 0x100>,  /*sram base*/
			      <0x0 0x04100000 0x0 0x1000>; /*otg base*/
			interrupts = <GIC_SPI 160 IRQ_TYPE_LEVEL_HIGH>;
			clocks = <&ccu CLK_USB1_OHCI>, <&ccu CLK_USB1>;
			clock-names = "bus_hci", "ohci";
			resets = <&ccu RST_USB_1_OHCI>, <&ccu RST_USB_1_PHY_RSTN>;
			reset-names = "hci", "phy";
			hci_ctrl_no = <1>;
			status = "disabled";
		};
	};
};
